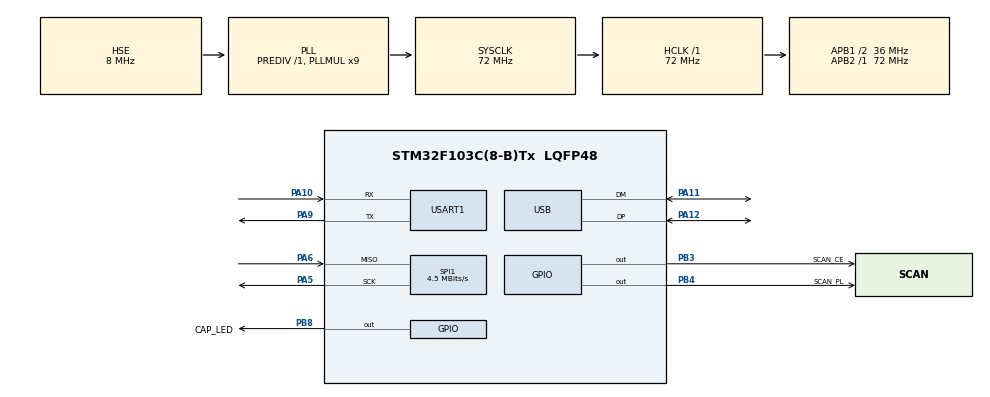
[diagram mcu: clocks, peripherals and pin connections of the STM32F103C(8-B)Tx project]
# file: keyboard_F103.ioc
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Mcu.Family=STM32F1
Mcu.Name=STM32F103C(8-B)Tx
Mcu.Package=LQFP48
NVIC.PriorityGroup=NVIC_PRIORITYGROUP_4
NVIC.TIM4_IRQn=true\:0\:0\:false\:false\:true\:true\:true\:true
NVIC.USB_LP_CAN1_RX0_IRQn=true\:0\:0\:false\:false\:true\:false\:true\:true
PA10.Mode=Asynchronous
PA10.Signal=USART1_RX
PA11.Mode=Device
PA11.Signal=USB_DM
PA12.Mode=Device
PA12.Signal=USB_DP
PA5.Mode=RX_Only_Simplex_Unidirect_Master
PA5.Signal=SPI1_SCK
PA6.Mode=RX_Only_Simplex_Unidirect_Master
PA6.Signal=SPI1_MISO
PA9.Mode=Asynchronous
PA9.Signal=USART1_TX
PB3.GPIO_Label=SCAN_CE
PB3.GPIO_PuPd=GPIO_NOPULL
PB3.GPIO_Speed=GPIO_SPEED_FREQ_LOW
PB3.Signal=GPIO_Output
PB4.GPIO_Label=SCAN_PL
PB4.GPIO_PuPd=GPIO_NOPULL
PB4.GPIO_Speed=GPIO_SPEED_FREQ_LOW
PB4.Signal=GPIO_Output
PB8.GPIO_Label=CAP_LED
PB8.GPIO_PuPd=GPIO_NOPULL
PB8.Signal=GPIO_Output
PD0-OSC_IN.Mode=HSE-External-Oscillator
PD0-OSC_IN.Signal=RCC_OSC_IN
PD1-OSC_OUT.Mode=HSE-External-Oscillator
PD1-OSC_OUT.Signal=RCC_OSC_OUT
ProjectManager.HeapSize=0x200
ProjectManager.StackSize=0x400
ProjectManager.TargetToolchain=MDK-ARM V5.32
RCC.AHBFreq_Value=72000000
RCC.APB1CLKDivider=RCC_HCLK_DIV2
RCC.APB1Freq_Value=36000000
RCC.APB1TimFreq_Value=72000000
RCC.APB2Freq_Value=72000000
RCC.APB2TimFreq_Value=72000000
RCC.HCLKFreq_Value=72000000
RCC.PLLMUL=RCC_PLL_MUL9
RCC.PLLSourceVirtual=RCC_PLLSOURCE_HSE
RCC.SYSCLKFreq_VALUE=72000000
RCC.SYSCLKSource=RCC_SYSCLKSOURCE_PLLCLK
RCC.USBFreq_Value=48000000
RCC.USBPrescaler=RCC_USBCLKSOURCE_PLL_DIV1_5
SPI1.BaudRatePrescaler=SPI_BAUDRATEPRESCALER_16
SPI1.CLKPhase=SPI_PHASE_1EDGE
SPI1.CLKPolarity=SPI_POLARITY_HIGH
SPI1.CalculateBaudRate=4.5 MBits/s
SPI1.Direction=SPI_DIRECTION_2LINES_RXONLY
SPI1.Mode=SPI_MODE_MASTER
SPI1.VirtualType=VM_MASTER
TIM4.AutoReloadPreload=TIM_AUTORELOAD_PRELOAD_ENABLE
TIM4.Period=999
TIM4.Prescaler=71
USART1.VirtualMode=VM_ASYNC
USB_DEVICE.CLASS_NAME_FS=CUSTOM_HID
USB_DEVICE.VirtualMode=CustomHid
USB_DEVICE.VirtualModeFS=Custom_Hid_FS
VP_SYS_VS_ND.Mode=No_Debug
VP_TIM4_VS_ClockSourceINT.Mode=Internal
VP_TIM4_VS_ClockSourceITR.Mode=TriggerSource_ITR0
VP_USB_DEVICE_VS_USB_DEVICE_CUSTOM_HID_FS.Mode=CUSTOM_HID_FS
board=custom

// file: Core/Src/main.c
/* USER CODE BEGIN Header */
/**
  ******************************************************************************
  * @file           : main.c
  * @brief          : Main program body
  ******************************************************************************
  * @attention
  *
  * Copyright (c) 2022 STMicroelectronics.
  * All rights reserved.
  *
  * This software is licensed under terms that can be found in the LICENSE file
  * in the root directory of this software component.
  * If no LICENSE file comes with this software, it is provided AS-IS.
  *
  ******************************************************************************
  */
/* USER CODE END Header */
#include "main.h"
#include "spi.h"
#include "tim.h"
#include "usart.h"
#include "usb_device.h"
#include "gpio.h"

/* USER CODE BEGIN Includes */
#include "stdio.h"
#include "usbd_custom_hid_if.h"
#include "hal_key.h"
/* USER CODE END Includes */

/* USER CODE BEGIN PM */
	extern USBD_HandleTypeDef hUsbDeviceFS;
/* USER CODE END PM */

void SystemClock_Config(void);

int main(void)
{

  /* MCU Configuration--------------------------------------------------------*/

  /* Reset of all peripherals, Initializes the Flash interface and the Systick. */
  HAL_Init();

  /* Configure the system clock */
  SystemClock_Config();

  /* Initialize all configured peripherals */
  MX_GPIO_Init();
  MX_SPI1_Init();
  MX_USART1_UART_Init();
  MX_USB_DEVICE_Init();
  MX_TIM4_Init();
  /* USER CODE BEGIN 2 */

	hal_key_init();
	// Keyboard Report Start

	printf("USB Keyboard\r\n");
  /* USER CODE END 2 */
  HAL_TIM_Base_Start_IT(&htim4);
  /* Infinite loop */
  while (1)
  {

  }
}

void SystemClock_Config(void)
{
  RCC_OscInitTypeDef RCC_OscInitStruct = {0};
  RCC_ClkInitTypeDef RCC_ClkInitStruct = {0};
  RCC_PeriphCLKInitTypeDef PeriphClkInit = {0};

  /** Initializes the RCC Oscillators according to the specified parameters
  * in the RCC_OscInitTypeDef structure.
  */
  RCC_OscInitStruct.OscillatorType = RCC_OSCILLATORTYPE_HSE;
  RCC_OscInitStruct.HSEState = RCC_HSE_ON;
  RCC_OscInitStruct.HSEPredivValue = RCC_HSE_PREDIV_DIV1;
  RCC_OscInitStruct.HSIState = RCC_HSI_ON;
  RCC_OscInitStruct.PLL.PLLState = RCC_PLL_ON;
  RCC_OscInitStruct.PLL.PLLSource = RCC_PLLSOURCE_HSE;
  RCC_OscInitStruct.PLL.PLLMUL = RCC_PLL_MUL9;
  if (HAL_RCC_OscConfig(&RCC_OscInitStruct) != HAL_OK)
  {
    Error_Handler();
  }

  /** Initializes the CPU, AHB and APB buses clocks
  */
  RCC_ClkInitStruct.ClockType = RCC_CLOCKTYPE_HCLK|RCC_CLOCKTYPE_SYSCLK
                              |RCC_CLOCKTYPE_PCLK1|RCC_CLOCKTYPE_PCLK2;
  RCC_ClkInitStruct.SYSCLKSource = RCC_SYSCLKSOURCE_PLLCLK;
  RCC_ClkInitStruct.AHBCLKDivider = RCC_SYSCLK_DIV1;
  RCC_ClkInitStruct.APB1CLKDivider = RCC_HCLK_DIV2;
  RCC_ClkInitStruct.APB2CLKDivider = RCC_HCLK_DIV1;

  if (HAL_RCC_ClockConfig(&RCC_ClkInitStruct, FLASH_LATENCY_2) != HAL_OK)
  {
    Error_Handler();
  }
  PeriphClkInit.PeriphClockSelection = RCC_PERIPHCLK_USB;
  PeriphClkInit.UsbClockSelection = RCC_USBCLKSOURCE_PLL_DIV1_5;
  if (HAL_RCCEx_PeriphCLKConfig(&PeriphClkInit) != HAL_OK)
  {
    Error_Handler();
  }
}

/* USER CODE BEGIN 4 */

void key_time_callback(void)
{
	//printf("%s\r\n", __func__ );
	hal_key_scan();
	hal_key_debounce(100);
	uint8_t* hid_buffer = key_remap();
	USBD_CUSTOM_HID_SendReport(&hUsbDeviceFS,
                               hid_buffer,
                               KEY_REPORT_SIZE);
}

/* USER CODE END 4 */

void Error_Handler(void)
{
  __disable_irq();
  while (1)
  {
  }
}
